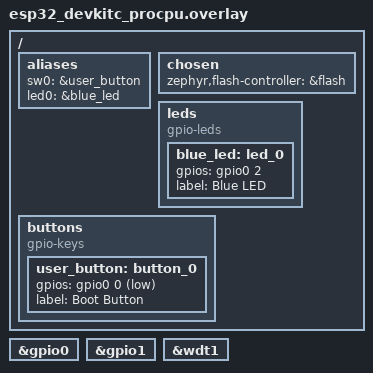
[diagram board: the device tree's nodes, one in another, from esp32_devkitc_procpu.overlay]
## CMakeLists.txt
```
cmake_minimum_required(VERSION 3.20.0)

find_package(Zephyr REQUIRED HINTS $ENV{ZEPHYR_BASE})

project(wol_procpu)

FILE(GLOB app_sources src/*.c)
target_sources(app PRIVATE ${app_sources})

target_include_directories(app PRIVATE
    ${CMAKE_SOURCE_DIR}/inc
    ${CMAKE_SOURCE_DIR}/../shared
)
```

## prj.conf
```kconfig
# --- General ---
CONFIG_EVENTS=y
CONFIG_THREAD_NAME=y
CONFIG_REBOOT=y
CONFIG_WATCHDOG=y

# --- Networking ---
CONFIG_NETWORKING=y
CONFIG_NET_IPV4=y
CONFIG_NET_UDP=y
CONFIG_NET_TCP=y
CONFIG_NET_SOCKETS=y
CONFIG_NET_MAX_CONN=10
CONFIG_NET_MAX_CONTEXTS=10
CONFIG_NET_L2_WIFI_MGMT=y
CONFIG_NET_MGMT=y
CONFIG_NET_MGMT_EVENT=y
CONFIG_NET_IPV4_AUTO=n
CONFIG_NET_DHCPV4=y

# --- Wi-Fi ---
CONFIG_WIFI=y
CONFIG_WIFI_ESP32=y
CONFIG_WIFI_INIT_PRIORITY=60

# --- Storage (NVS Flash) ---
CONFIG_FLASH=y
CONFIG_FLASH_MAP=y
CONFIG_NVS=y
CONFIG_FLASH_PAGE_LAYOUT=y

# --- Hardware ---
CONFIG_GPIO=y

# --- HEAD / STACK ---
CONFIG_LOG_BUFFER_SIZE=1024
CONFIG_LOG_PROCESS_THREAD_STACK_SIZE=1536
CONFIG_NET_MGMT_EVENT_STACK_SIZE=1024
CONFIG_NET_TCP_WORKQ_STACK_SIZE=512
CONFIG_MAIN_STACK_SIZE=4096
CONFIG_SYSTEM_WORKQUEUE_STACK_SIZE=2048
CONFIG_HEAP_MEM_POOL_SIZE=65536
CONFIG_ISR_STACK_SIZE=32768
CONFIG_NET_RX_STACK_SIZE=4096
CONFIG_NET_TX_STACK_SIZE=4096

# --- DEBUG ---
CONFIG_LOG=y
#CONFIG_CONSOLE=n
#CONFIG_UART_CONSOLE=n
CONFIG_THREAD_ANALYZER=y
CONFIG_THREAD_ANALYZER_AUTO=y
CONFIG_THREAD_ANALYZER_AUTO_INTERVAL=30
```

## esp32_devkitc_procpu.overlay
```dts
#include <zephyr/dt-bindings/input/input-event-codes.h>

/ {
	aliases {
		sw0 = &user_button;
		led0 = &blue_led;
	};

	chosen {
		zephyr,flash-controller = &flash;
	};

	leds {
		compatible = "gpio-leds";

		blue_led: led_0 {
			gpios = <&gpio0 2 GPIO_ACTIVE_HIGH>;
			label = "Blue LED";
		};
	};

	buttons {
		compatible = "gpio-keys";

		user_button: button_0 {
			gpios = <&gpio0 0 (GPIO_PULL_UP | GPIO_ACTIVE_LOW)>;
			label = "Boot Button";
		};
	};
};

&gpio0 { status = "okay"; };
&gpio1 { status = "okay"; };
&wdt1  { status = "okay"; };
```

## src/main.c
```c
#include <zephyr/kernel.h>
#include <zephyr/drivers/watchdog.h>
#include <zephyr/sys/reboot.h>
#include <string.h>
#include <stdio.h>

#include "storage.h"
#include "notify.h"
#include "button.h"
#include "wifi.h"
#include "portal.h"
#include "display.h"

#define WDT_TIMEOUT_MS  5000

int main(void) {
    k_msleep(100);

#ifdef CONFIG_SOC_ESP32
    /* Zero shared memory BEFORE appcpu reads it */
    memset((void *)SHARED_STATE(), 0, sizeof(shared_display_state_t));
#endif

    const struct device *wdt_dev = DEVICE_DT_GET(DT_NODELABEL(wdt1));
    int wdt_channel = -1;

    char ssid[32], pass[64], mac[18], pc_ip[INET_ADDRSTRLEN];

    storage_init();
    notify_init();
    button_init();

    if (device_is_ready(wdt_dev)) {
        struct wdt_timeout_cfg wdt_config = {
            .window.max = WDT_TIMEOUT_MS,
            .flags = WDT_FLAG_RESET_SOC
        };
        wdt_channel = wdt_install_timeout(wdt_dev, &wdt_config);
        wdt_setup(wdt_dev, WDT_OPT_PAUSE_HALTED_BY_DBG);
    }

    int rc = storage_read_config(ssid, pass, mac, pc_ip);

    if (rc == 0 && strlen(ssid) > 0 && strlen(mac) == 17) {
        printf("[SYSTEM] Config loaded. Starting Station mode...\n");
        wifi_init_and_connect(ssid, pass, mac, pc_ip);
    } else {
        if (rc == 0) {
            printf("[SYSTEM] Invalid config in Flash. Clearing...\n");
            storage_clear_all();
        }
        printf("[SYSTEM] Starting Portal...\n");
        start_portal();
    }

    printf("\n--- Wake-on-LAN ESP32 DevKitC ---\n");

    while (1) {
#ifdef CONFIG_SOC_ESP32
        bool current_has_ip = SHARED_STATE()->has_ip;
#else
        bool current_has_ip = has_ip;
#endif

        if (!current_has_ip) {
            if (button_is_pressed()) {
                printf("[SYSTEM] FACTORY RESET ACTIVATED!\n");
                storage_clear_all();
                notify_event(NOTIFY_WOL_SENT);
                k_msleep(1000);
                sys_reboot(SYS_REBOOT_COLD);
            }
        }

        if (wdt_channel >= 0) {
            wdt_feed(wdt_dev, wdt_channel);
        }

        k_msleep(500);
    }

    return 0;
}
```

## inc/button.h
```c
#ifndef BUTTON_H
#define BUTTON_H

#include <zephyr/kernel.h>
#include <zephyr/device.h>
#include <zephyr/drivers/gpio.h>
#include <stdio.h>
#include <stdbool.h>

/**
 * @brief Initializes the BOOT button GPIO and its interrupt.
 *        On press: triggers WoL via trigger_wol().
 */
void button_init(void);

/**
 * @brief Checks if the BOOT button is currently pressed.
 *
 * @return true if pressed, false otherwise.
 */
bool button_is_pressed(void);

#endif /* BUTTON_H */
```

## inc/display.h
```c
#ifndef DISPLAY_H
#define DISPLAY_H

#include <zephyr/kernel.h>
#include <zephyr/net/net_ip.h>
#include <stdbool.h>

#ifdef CONFIG_SOC_ESP32

/* On DevKitC (dual-core): display state lives in shared memory.
 * procpu only writes to shared state — no local display variables. */
#include "shared_mem.h"

static inline void display_set_ap_mode(bool v)      { SHARED_STATE()->display_ap_mode    = v; }
static inline void display_set_has_ip(bool v)        { SHARED_STATE()->has_ip              = v; }
static inline void display_notify_start(void)        { SHARED_STATE()->display_start_flag  = 1; }
static inline void display_notify_refresh(void)      { SHARED_STATE()->ui_refresh_flag     = 1; }

/* Compatibility shims so existing call sites in notify.c / wifi.c compile unchanged.
 * sem_ui_refresh and sem_display_start are never used on procpu in dual-core mode —
 * replaced by shared memory flags. Defined as 0 to satisfy the compiler without
 * requiring a real k_sem object. fix #9: removed extern _display_noop_sem. */
#define display_station_ready   (1)
#define sem_ui_refresh          (*((struct k_sem *)NULL))   /* never dereferenced on procpu */
#define sem_display_start       (*((struct k_sem *)NULL))

#else

/* On ESP32-C3 (single-core): original semaphore-based interface */
extern struct k_sem sem_display_start;
extern struct k_sem sem_ui_refresh;

extern bool display_ap_mode;
extern bool display_wifi_ready;
extern bool display_station_ready;
extern bool has_ip;

#endif /* CONFIG_SOC_ESP32 */

void display_task_entry(void *p1, void *p2, void *p3);

#endif /* DISPLAY_H */
```

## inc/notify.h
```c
#ifndef NOTIFY_H
#define NOTIFY_H

#include <zephyr/kernel.h>
#include <zephyr/drivers/gpio.h>

/* Notification types */
typedef enum {
    NOTIFY_WOL_SENT,    /* 2 Blinks (500ms ON, 200ms OFF) */
    NOTIFY_PING_UPDATE  /* 1 Blink  (500ms ON) */
} notify_type_t;

/**
 * @brief Initialize GPIO for the Blue LED.
 */
void notify_init(void);

/**
 * @brief Notify the user of an event by blinking the blue LED.
 *        Also signals the display to refresh (shared memory on DevKitC,
 *        semaphore on ESP32-C3).
 *
 *        - NOTIFY_WOL_SENT:   2 blinks (500ms ON, 200ms OFF)
 *        - NOTIFY_PING_UPDATE: 1 blink  (500ms ON)
 */
void notify_event(notify_type_t type);

#endif /* NOTIFY_H */
```

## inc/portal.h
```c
#ifndef PORTAL_H
#define PORTAL_H

#include <zephyr/kernel.h>
#include <zephyr/net/socket.h>
#include <zephyr/net/wifi_mgmt.h>
#include <zephyr/net/net_if.h>
#include <zephyr/net/net_mgmt.h>
#include <zephyr/net/net_ip.h>
#include <zephyr/sys/reboot.h>
#include <stdlib.h>
#include <string.h>
#include <ctype.h>

/**
 * @brief Starts the Captive Portal.
 *
 * 1. Enables Wi-Fi Access Point mode (SSID: WOL_ESP).
 * 2. Sets a static IP (192.168.4.1).
 * 3. Starts the DNS redirector task (intercepts all DNS queries).
 * 4. Starts the HTTP server (serves the configuration form).
 *
 * On ESP32 DevKitC (dual-core): also signals the appcpu display
 * thread via shared memory before starting the AP.
 */
void start_portal(void);

/**
 * @brief Stops the Captive Portal and disables AP mode.
 */
void stop_portal(void);

#endif /* PORTAL_H */
```

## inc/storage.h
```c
#ifndef STORAGE_H
#define STORAGE_H

#include <zephyr/kernel.h>
#include <zephyr/device.h>
#include <zephyr/drivers/flash.h>
#include <zephyr/fs/nvs.h>
#include <zephyr/net/net_ip.h>
#include <string.h>
#include <zephyr/types.h>

/* Unique IDs for each NVS entry */
#define STORAGE_ID_SSID     1
#define STORAGE_ID_PASS     2
#define STORAGE_ID_MAC      3
#define STORAGE_ID_IP       4

/**
 * @brief Initializes the NVS storage subsystem.
 */
void storage_init(void);

/**
 * @brief Saves Wi-Fi settings and target PC MAC/IP to Flash.
 *
 * @param s  Wi-Fi SSID.
 * @param p  Wi-Fi password.
 * @param m  Target MAC address ("AA:BB:CC:DD:EE:FF").
 * @param ip Target PC IP address ("192.168.1.100").
 * @return 0 on success.
 */
int storage_write_config(const char *s, const char *p,
                         const char *m, const char *ip);

/**
 * @brief Reads saved settings from Flash.
 *
 * @param s  Buffer for SSID  (min 32 bytes).
 * @param p  Buffer for password (min 64 bytes).
 * @param m  Buffer for MAC   (min 18 bytes).
 * @param ip Buffer for IP    (min INET_ADDRSTRLEN bytes).
 * @return 0 on success, -1 if Flash is empty.
 */
int storage_read_config(char *s, char *p, char *m, char *ip);

/**
 * @brief Erases all settings from Flash (Factory Reset).
 */
void storage_clear_all(void);

#endif /* STORAGE_H */
```

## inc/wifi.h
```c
#ifndef WIFI_H
#define WIFI_H

#include <zephyr/kernel.h>
#include <zephyr/net/net_if.h>
#include <zephyr/net/net_mgmt.h>
#include <zephyr/net/wifi_mgmt.h>
#include <zephyr/net/net_event.h>
#include <zephyr/net/socket.h>
#include <zephyr/net/icmp.h>
#include <zephyr/net/net_ip.h>
#include <zephyr/net/dhcpv4.h>
#include <stdio.h>
#include <string.h>
#include <errno.h>
#include <stdbool.h>

/**
 * Global variables — defined in wifi.c.
 *
 * On ESP32-C3 (single-core): accessed directly by display.c.
 * On ESP32 DevKitC (dual-core): procpu-local only; display reads
 * from shared memory via shared_mem.h instead.
 */
extern char global_ip_str[INET_ADDRSTRLEN];
extern bool last_known_state;
extern char target_pc_ip[INET_ADDRSTRLEN];

/**
 * @brief Initializes the Wi-Fi stack and attempts to connect.
 *
 * @param ssid  The Wi-Fi network name from Flash.
 * @param pass  The Wi-Fi password from Flash.
 * @param mac   The target PC MAC address (string "AA:BB:CC:DD:EE:FF").
 * @param pc_ip The target PC IP address (string "192.168.1.100").
 */
void wifi_init_and_connect(const char *ssid, const char *pass,
                           const char *mac,  const char *pc_ip);

/**
 * @brief Submits a Wake-on-LAN Magic Packet task to the system workqueue.
 *        Called by the button interrupt handler in button.c.
 */
void trigger_wol(void);

#endif /* WIFI_H */
```

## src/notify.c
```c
#include "notify.h"
#include "display.h"

static const struct gpio_dt_spec blue_led = GPIO_DT_SPEC_GET(DT_NODELABEL(blue_led), gpios);

static K_SEM_DEFINE(sem_blink, 0, 1);
static int blink_count;

static void blink_thread(void *p1, void *p2, void *p3) {
    while (1) {
        k_sem_take(&sem_blink, K_FOREVER);

        for (int i = 0; i < blink_count; i++) {
            gpio_pin_set_dt(&blue_led, 1);
            k_msleep(500);
            gpio_pin_set_dt(&blue_led, 0);
            if (i < blink_count - 1) {
                k_msleep(200);
            }
        }
    }
}
K_THREAD_DEFINE(blink_tid, 512, blink_thread, NULL, NULL, NULL, 10, 0, 0);

void notify_init(void) {
    if (!device_is_ready(blue_led.port)) {
        return;
    }
    gpio_pin_configure_dt(&blue_led, GPIO_OUTPUT_INACTIVE);
}

void notify_event(notify_type_t type) {
#ifdef CONFIG_SOC_ESP32
    /* Dual-core: signal appcpu via shared memory flag */
    display_notify_refresh();
#else
    /* Single-core: original semaphore */
    if (display_station_ready) {
        k_sem_give(&sem_ui_refresh);
    }
#endif

    blink_count = (type == NOTIFY_WOL_SENT) ? 2 : 1;
    k_sem_give(&sem_blink);
}
```

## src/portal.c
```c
#include "portal.h"
#include "portal_html.h"
#include "storage.h"
#include "notify.h"
#include "display.h"

static bool portal_active = false;

static void send_all(int sock, const char *data, int len) {
    while (len > 0) {
        int sent = zsock_send(sock, data, len, 0);
        if (sent <= 0) break;
        data += sent;
        len  -= sent;
    }
}

static void send_form(int client, bool with_err) {
    const char *hdr =
        "HTTP/1.1 200 OK\r\nContent-Type: text/html\r\n"
        "Connection: close\r\n\r\n";
    send_all(client, hdr,     strlen(hdr));
    send_all(client, html_p1, strlen(html_p1));
    send_all(client, html_p2, strlen(html_p2));
    send_all(client, html_p3, strlen(html_p3));
    send_all(client, html_p4, strlen(html_p4));
    if (with_err) {
        send_all(client, html_err, strlen(html_err));
    }
    send_all(client, html_tail, strlen(html_tail));
}

static void extract_field(const char *body, const char *key, char *out, size_t out_len) {
    const char *p = strstr(body, key);
    if (!p) { out[0] = '\0'; return; }
    p += strlen(key) + 1;
    size_t i = 0;
    while (*p && *p != '&' && i < out_len - 1) {
        out[i++] = *p++;
    }
    out[i] = '\0';
}

static void url_decode(char *dst, const char *src, size_t dst_len) {
    size_t i = 0;
    while (*src && i < dst_len - 1) {
        if (*src == '%' && src[1] && src[2]) {
            char hex[3] = { src[1], src[2], '\0' };
            dst[i++] = (char)strtol(hex, NULL, 16);
            src += 3;
        } else if (*src == '+') {
            dst[i++] = ' ';
            src++;
        } else {
            dst[i++] = *src++;
        }
    }
    dst[i] = '\0';
}

static bool is_valid_mac(const char *mac) {
    if (strlen(mac) != 17) return false;
    for (int i = 0; i < 17; i++) {
        if (i % 3 == 2) {
            if (mac[i] != ':') return false;
        } else {
            if (!isxdigit((unsigned char)mac[i])) return false;
        }
    }
    return true;
}

static void http_server_task(void *p1, void *p2, void *p3) {
    while (!portal_active) { k_msleep(100); }

    int server = zsock_socket(AF_INET, SOCK_STREAM, IPPROTO_TCP);
    if (server < 0) { return; }

    int opt = 1;
    zsock_setsockopt(server, SOL_SOCKET, SO_REUSEADDR, &opt, sizeof(opt));

    struct sockaddr_in addr = {
        .sin_family      = AF_INET,
        .sin_port        = htons(80),
        .sin_addr.s_addr = INADDR_ANY,
    };
    zsock_bind(server, (struct sockaddr *)&addr, sizeof(addr));
    zsock_listen(server, 2);

    static char buf[1024];

    while (1) {
        int client = zsock_accept(server, NULL, NULL);
        if (client < 0) continue;

        int total = 0, content_length = 0;
        bool headers_done = false;
        char *body_start = NULL;
        memset(buf, 0, sizeof(buf));

        while (total < (int)sizeof(buf) - 1) {
            int n = zsock_recv(client, buf + total, sizeof(buf) - 1 - total, 0);
            if (n <= 0) break;
            total += n;
            buf[total] = '\0';

            if (!headers_done) {
                body_start = strstr(buf, "\r\n\r\n");
                if (body_start) {
                    headers_done = true;
                    body_start += 4;
                    char *cl = strstr(buf, "Content-Length:");
                    if (!cl) cl = strstr(buf, "content-length:");
                    if (cl) content_length = atoi(cl + 15);
                }
            }
            if (headers_done && content_length > 0) {
                if ((total - (int)(body_start - buf)) >= content_length) break;
            } else if (headers_done) {
                break;
            }
        }

        if (!headers_done || !body_start) { zsock_close(client); continue; }

        if (strncmp(buf, "POST /save", 10) == 0) {
            char raw_ssid[32]={0}, raw_pass[64]={0}, raw_mac[64]={0}, raw_ip[32]={0};
            extract_field(body_start, "s", raw_ssid, sizeof(raw_ssid));
            extract_field(body_start, "p", raw_pass, sizeof(raw_pass));
            extract_field(body_start, "i", raw_ip,   sizeof(raw_ip));
            extract_field(body_start, "m", raw_mac,  sizeof(raw_mac));

            char ssid[32]={0}, pass[64]={0}, mac[18]={0}, pc_ip[INET_ADDRSTRLEN]={0};
            url_decode(ssid,  raw_ssid, sizeof(ssid));
            url_decode(pass,  raw_pass, sizeof(pass));
            url_decode(pc_ip, raw_ip,   sizeof(pc_ip));
            url_decode(mac,   raw_mac,  sizeof(mac));

            struct in_addr tmp;
            bool ip_ok = (strlen(pc_ip) > 0 && zsock_inet_pton(AF_INET, pc_ip, &tmp) == 1);

            if (strlen(ssid) == 0 || !is_valid_mac(mac) || !ip_ok) {
                send_form(client, true);
                zsock_close(client);
                continue;
            }

            storage_write_config(ssid, pass, mac, pc_ip);
            send_all(client, html_ok, strlen(html_ok));
            k_msleep(200);
            zsock_close(client);
            notify_event(NOTIFY_WOL_SENT);
            k_msleep(1000);
            sys_reboot(SYS_REBOOT_COLD);
        } else {
            send_form(client, false);
        }
        zsock_close(client);
    }
}
K_THREAD_DEFINE(http_tid, 4096, http_server_task, NULL, NULL, NULL, 7, 0, 0);

static void dhcp_server_task(void *p1, void *p2, void *p3) {
    while (!portal_active) { k_msleep(100); }

    int sock = zsock_socket(AF_INET, SOCK_DGRAM, IPPROTO_UDP);
    if (sock < 0) { return; }

    int opt = 1;
    zsock_setsockopt(sock, SOL_SOCKET, SO_REUSEADDR, &opt, sizeof(opt));

    struct sockaddr_in addr = {
        .sin_family      = AF_INET,
        .sin_port        = htons(67),
        .sin_addr.s_addr = INADDR_ANY,
    };
    zsock_bind(sock, (struct sockaddr *)&addr, sizeof(addr));

    uint8_t buf[300];
    while (1) {
        struct sockaddr_in client_addr;
        socklen_t addr_len = sizeof(client_addr);
        int len = zsock_recvfrom(sock, buf, sizeof(buf), 0,
                                 (struct sockaddr *)&client_addr, &addr_len);
        if (len < 240 || buf[0] != 1) continue;

        uint8_t reply[300];
        memset(reply, 0, sizeof(reply));
        reply[0] = 2; reply[1] = buf[1]; reply[2] = buf[2]; reply[3] = buf[3];
        memcpy(&reply[4], &buf[4], 4);
        reply[10] = buf[10]; reply[11] = buf[11];
        reply[16] = 192; reply[17] = 168; reply[18] = 4; reply[19] = 2;
        reply[20] = 192; reply[21] = 168; reply[22] = 4; reply[23] = 1;
        memcpy(&reply[28], &buf[28], 6);
        reply[236] = 99; reply[237] = 130; reply[238] = 83; reply[239] = 99;

        int i = 240;
        uint8_t msg_type = (buf[242] == 1) ? 2 : 5;
        reply[i++] = 53; reply[i++] = 1; reply[i++] = msg_type;
        reply[i++] = 54; reply[i++] = 4;
        reply[i++] = 192; reply[i++] = 168; reply[i++] = 4; reply[i++] = 1;
        reply[i++] = 51; reply[i++] = 4;
        reply[i++] = 0; reply[i++] = 0; reply[i++] = 0x0e; reply[i++] = 0x10;
        reply[i++] = 1; reply[i++] = 4;
        reply[i++] = 255; reply[i++] = 255; reply[i++] = 255; reply[i++] = 0;
        reply[i++] = 3; reply[i++] = 4;
        reply[i++] = 192; reply[i++] = 168; reply[i++] = 4; reply[i++] = 1;
        reply[i++] = 6; reply[i++] = 4;
        reply[i++] = 192; reply[i++] = 168; reply[i++] = 4; reply[i++] = 1;
        reply[i++] = 255;

        struct sockaddr_in dst = {
            .sin_family      = AF_INET,
            .sin_port        = htons(68),
            .sin_addr.s_addr = INADDR_BROADCAST,
        };
        zsock_sendto(sock, reply, i, 0, (struct sockaddr *)&dst, sizeof(dst));
    }
}
K_THREAD_DEFINE(dhcp_tid, 2048, dhcp_server_task, NULL, NULL, NULL, 7, 0, 0);

static void dns_server_task(void *p1, void *p2, void *p3) {
    while (!portal_active) { k_msleep(100); }

    int sock = zsock_socket(AF_INET, SOCK_DGRAM, IPPROTO_UDP);
    if (sock < 0) { return; }

    struct sockaddr_in addr = {
        .sin_family      = AF_INET,
        .sin_port        = htons(53),
        .sin_addr.s_addr = INADDR_ANY,
    };
    zsock_bind(sock, (struct sockaddr *)&addr, sizeof(addr));

    uint8_t buffer[512];
    while (1) {
        struct sockaddr client_addr;
        socklen_t addr_len = sizeof(client_addr);
        int len = zsock_recvfrom(sock, buffer, sizeof(buffer), 0,
                                 &client_addr, &addr_len);
        if (len > 0) {
            buffer[2] |= 0x80;
            zsock_sendto(sock, buffer, len, 0, &client_addr, addr_len);
        }
    }
}
K_THREAD_DEFINE(dns_tid, 2048, dns_server_task, NULL, NULL, NULL, 8, 0, 0);

void start_portal(void) {
#ifdef CONFIG_SOC_ESP32
    SHARED_STATE()->display_ap_mode = true;
    display_notify_start();
#else
    display_ap_mode = true;
#endif

    struct net_if *iface = net_if_get_default();
    struct in_addr gw, mask, my_addr;
    zsock_inet_pton(AF_INET, "192.168.4.1", &my_addr);
    zsock_inet_pton(AF_INET, "192.168.4.1", &gw);
    zsock_inet_pton(AF_INET, "255.255.255.0", &mask);
    net_if_ipv4_set_gw(iface, &gw);
    net_if_ipv4_addr_add(iface, &my_addr, NET_ADDR_MANUAL, 0);
    net_if_ipv4_set_netmask_by_addr(iface, &my_addr, &mask);

    struct wifi_connect_req_params params = {
        .ssid        = "WOL_ESP",
        .ssid_length = 7,
        .security    = WIFI_SECURITY_TYPE_NONE,
        .channel     = 1,
        .band        = WIFI_FREQ_BAND_2_4_GHZ,
        .mfp         = WIFI_MFP_DISABLE,
    };

    printk("[PORTAL] AP Mode Starting...\n");
    int ret = net_mgmt(NET_REQUEST_WIFI_AP_ENABLE, iface, &params, sizeof(params));
    if (ret) {
        printk("[PORTAL] AP enable failed: %d\n", ret);
        return;
    }
    printk("[PORTAL] AP up: 192.168.4.1\n");
    portal_active = true;
}
```

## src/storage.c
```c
#include "storage.h"

#define STORAGE_NODE DT_NODE_BY_FIXED_PARTITION_LABEL(storage)
#define FLASH_NODE DT_MTD_FROM_FIXED_PARTITION(STORAGE_NODE)

static struct nvs_fs fs;

void storage_init(void) {
    int rc;
    struct flash_pages_info info;
    const struct device *flash_dev = DEVICE_DT_GET(FLASH_NODE);

    if (!device_is_ready(flash_dev)) {
        printk("Error: Flash device not ready\n");
        return;
    }

    fs.flash_device = flash_dev;
    fs.offset = DT_REG_ADDR(STORAGE_NODE);
    
    rc = flash_get_page_info_by_offs(flash_dev, fs.offset, &info);
    if (rc) {
        printk("Error getting page info (%d)\n", rc);
        return;
    }

    fs.sector_size = info.size;
    fs.sector_count = 3;                                                /* Reserve 3 sectors for NVS */

    rc = nvs_mount(&fs);
    if (rc) {
        printk("Error mounting NVS (%d)\n", rc);
    }
}

int storage_write_config(const char *s, const char *p, const char *m, const char *ip) {
    nvs_write(&fs, STORAGE_ID_SSID, s,  strlen(s)  + 1);
    nvs_write(&fs, STORAGE_ID_PASS, p,  strlen(p)  + 1);
    nvs_write(&fs, STORAGE_ID_MAC,  m,  strlen(m)  + 1);
    nvs_write(&fs, STORAGE_ID_IP,   ip, strlen(ip) + 1);
    return 0;
}

int storage_read_config(char *s, char *p, char *m, char *ip) {
    if (nvs_read(&fs, STORAGE_ID_SSID, s, 32) <= 0) return -1;
    nvs_read(&fs, STORAGE_ID_PASS, p,  64);
    nvs_read(&fs, STORAGE_ID_MAC,  m,  18);
    nvs_read(&fs, STORAGE_ID_IP,   ip, INET_ADDRSTRLEN);
    return 0;
}

void storage_clear_all(void) {
    nvs_delete(&fs, STORAGE_ID_SSID);
    nvs_delete(&fs, STORAGE_ID_PASS);
    nvs_delete(&fs, STORAGE_ID_MAC);
    nvs_delete(&fs, STORAGE_ID_IP);
}
```

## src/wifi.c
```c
#include "wifi.h"
#include "notify.h"
#include "storage.h"
#include "display.h"

#define WOL_PORT    9

static struct net_icmp_ctx ping_ctx;
static struct k_work_delayable ping_work;
static volatile bool target_is_online   = false;
bool last_known_state                   = false;
static bool first_ping_done             = false;
static uint16_t ping_seq                = 0;
static uint8_t ping_attempts            = 0;

static bool wifi_connected              = false;

static char saved_ssid[32];
static char saved_pass[64];
static char saved_mac_str[18];
static uint8_t target_mac_bin[6];
char target_pc_ip[INET_ADDRSTRLEN]      = "255.255.255.255";
char global_ip_str[INET_ADDRSTRLEN]     = "";

static struct net_mgmt_event_callback wifi_cb;
static struct net_mgmt_event_callback ipv4_cb;
static struct k_work wol_work;
static struct k_work_delayable reconnect_work;

/* --- Shared memory sync helper --- */
static inline void sync_to_shared(void) {
#ifdef CONFIG_SOC_ESP32
    volatile shared_display_state_t *s = SHARED_STATE();
    strncpy((char *)s->global_ip_str, global_ip_str, sizeof(s->global_ip_str) - 1);
    strncpy((char *)s->target_pc_ip,  target_pc_ip,  sizeof(s->target_pc_ip)  - 1);
    s->last_known_state = last_known_state;
    s->has_ip = (strlen(global_ip_str) > 0 && strcmp(global_ip_str, "0.0.0.0") != 0);
#endif
}

static void parse_mac_address(const char *mac_str, uint8_t *mac_bin) {
    for (int i = 0; i < 6; i++) {
        char byte_str[3] = { mac_str[i * 3], mac_str[i * 3 + 1], '\0' };
        mac_bin[i] = (uint8_t)strtol(byte_str, NULL, 16);
    }
}

static void reconnect_worker(struct k_work *work) {
    struct net_if *iface = net_if_get_default();
    struct wifi_connect_req_params params = {
        .ssid        = (uint8_t *)saved_ssid,
        .ssid_length = strlen(saved_ssid),
        .psk         = (uint8_t *)saved_pass,
        .psk_length  = strlen(saved_pass),
        .channel     = WIFI_CHANNEL_ANY,
        .security    = WIFI_SECURITY_TYPE_PSK,
        .band        = WIFI_FREQ_BAND_2_4_GHZ,
    };
    printk("[WIFI] Reconnecting to %s...\n", saved_ssid);
    net_mgmt(NET_REQUEST_WIFI_CONNECT, iface, &params, sizeof(params));
}

static void send_wol_worker(struct k_work *work) {
    if (strlen(global_ip_str) == 0 || strcmp(global_ip_str, "0.0.0.0") == 0) {
        printk("[WOL] No IP — WoL cancelled\n");
        return;
    }

    uint8_t pkt[102];
    struct sockaddr_in dest;

    memset(pkt, 0xFF, 6);
    for (int i = 1; i <= 16; i++) {
        memcpy(&pkt[i * 6], target_mac_bin, 6);
    }

    int sock = zsock_socket(AF_INET, SOCK_DGRAM, IPPROTO_UDP);
    if (sock < 0) { return; }

    int opt = 1;
    zsock_setsockopt(sock, SOL_SOCKET, SO_BROADCAST, &opt, sizeof(opt));

    dest.sin_family      = AF_INET;
    dest.sin_port        = htons(WOL_PORT);
    dest.sin_addr.s_addr = INADDR_BROADCAST;

    if (zsock_sendto(sock, pkt, sizeof(pkt), 0,
                     (struct sockaddr *)&dest, sizeof(dest)) > 0) {
        printk("[WIFI] WoL Magic Packet Sent to %s\n", saved_mac_str);
        notify_event(NOTIFY_WOL_SENT);
    }
    zsock_close(sock);
}

void trigger_wol(void) {
    k_work_submit(&wol_work);
}

static int ping_handler(struct net_icmp_ctx *ctx, struct net_pkt *pkt,
                        struct net_icmp_ip_hdr *ip_hdr, struct net_icmp_hdr *icmp_hdr,
                        void *user_data) {
    target_is_online = true;
    return 0;
}

static void ping_worker_handler(struct k_work *work) {
    if (ping_attempts > 0) {
        if (target_is_online) {
            if (!first_ping_done || !last_known_state) {
                last_known_state = true;
                first_ping_done  = true;
                sync_to_shared();
                notify_event(NOTIFY_PING_UPDATE);
            }
            ping_attempts = 0;
            k_work_reschedule(&ping_work, K_MINUTES(1));
            return;
        } else if (ping_attempts >= 3) {
            if (!first_ping_done || last_known_state) {
                last_known_state = false;
                first_ping_done  = true;
                sync_to_shared();
                notify_event(NOTIFY_PING_UPDATE);
            }
            ping_attempts = 0;
            k_work_reschedule(&ping_work, K_MINUTES(1));
            return;
        }
    }

    target_is_online = false;
    ping_attempts++;

    struct sockaddr_in dest;
    dest.sin_family = AF_INET;
    zsock_inet_pton(AF_INET, target_pc_ip, &dest.sin_addr);

    struct net_icmp_ping_params params = {
        .identifier = 0x1234,
        .sequence   = ping_seq++,
    };

    net_icmp_send_echo_request(&ping_ctx, net_if_get_default(),
                               (struct sockaddr *)&dest, &params, NULL);
    k_work_reschedule(&ping_work, K_SECONDS(1));
}

static void handle_wifi_events(struct net_mgmt_event_callback *cb,
                                uint64_t mgmt_event, struct net_if *iface) {
    if (mgmt_event == NET_EVENT_WIFI_CONNECT_RESULT) {
        wifi_connected = true;
        printk("[WIFI] Connected!\n");
        net_dhcpv4_start(iface);
    }

    if (mgmt_event == NET_EVENT_WIFI_DISCONNECT_RESULT) {
        if (!wifi_connected) return;
        wifi_connected = false;
        printk("[WIFI] Disconnected — reconnecting in 3s...\n");
        net_dhcpv4_stop(iface);
        last_known_state = false;
        global_ip_str[0] = '\0';
        sync_to_shared();
#ifdef CONFIG_SOC_ESP32
        display_notify_refresh();
#else
        k_sem_give(&sem_ui_refresh);
#endif
        k_work_reschedule(&reconnect_work, K_SECONDS(3));
    }
}

static void handle_ipv4_events(struct net_mgmt_event_callback *cb,
                                uint64_t mgmt_event, struct net_if *iface) {
    if (mgmt_event == NET_EVENT_IPV4_ADDR_ADD) {
        struct net_if_ipv4 *ipv4 = iface->config.ip.ipv4;
        if (!ipv4) return;

        for (int i = 0; i < NET_IF_MAX_IPV4_ADDR; i++) {
            struct net_if_addr *addr = &ipv4->unicast[i].ipv4;
            if (addr->is_used && addr->addr_state == NET_ADDR_PREFERRED) {
                zsock_inet_ntop(AF_INET,
                    &ipv4->unicast[i].ipv4.address.in_addr,
                    global_ip_str, sizeof(global_ip_str));
                sync_to_shared();
#ifdef CONFIG_SOC_ESP32
                display_notify_refresh();
#else
                k_sem_give(&sem_ui_refresh);
#endif
                k_work_reschedule(&ping_work, K_NO_WAIT);
                break;
            }
        }
    }
}

void wifi_init_and_connect(const char *ssid, const char *pass, const char *mac, const char *pc_ip) {
    strncpy(saved_ssid,    ssid, sizeof(saved_ssid) - 1);
    strncpy(saved_pass,    pass, sizeof(saved_pass) - 1);
    strncpy(saved_mac_str, mac,  sizeof(saved_mac_str) - 1);
    strncpy(target_pc_ip,  pc_ip, sizeof(target_pc_ip) - 1);

    parse_mac_address(saved_mac_str, target_mac_bin);

    /* Initialise shared memory region */
    sync_to_shared();
#ifdef CONFIG_SOC_ESP32
    strncpy((char *)SHARED_STATE()->target_pc_ip, target_pc_ip, INET_ADDRSTRLEN - 1);
#endif

    k_work_init(&wol_work, send_wol_worker);
    k_work_init_delayable(&ping_work, ping_worker_handler);
    k_work_init_delayable(&reconnect_work, reconnect_worker);
    net_icmp_init_ctx(&ping_ctx, AF_INET, NET_ICMPV4_ECHO_REPLY, 0, ping_handler);

    net_mgmt_init_event_callback(&wifi_cb, handle_wifi_events,
                              NET_EVENT_WIFI_CONNECT_RESULT |
                              NET_EVENT_WIFI_DISCONNECT_RESULT);
    net_mgmt_add_event_callback(&wifi_cb);

    net_mgmt_init_event_callback(&ipv4_cb, handle_ipv4_events,
                                  NET_EVENT_IPV4_ADDR_ADD);
    net_mgmt_add_event_callback(&ipv4_cb);

    struct net_if *iface = net_if_get_default();
    struct wifi_connect_req_params params = {
        .ssid        = (uint8_t *)saved_ssid,
        .ssid_length = strlen(saved_ssid),
        .psk         = (uint8_t *)saved_pass,
        .psk_length  = strlen(saved_pass),
        .channel     = WIFI_CHANNEL_ANY,
        .security    = WIFI_SECURITY_TYPE_PSK,
        .band        = WIFI_FREQ_BAND_2_4_GHZ,
    };

#ifdef CONFIG_SOC_ESP32
    display_notify_start();   /* signal appcpu to start display thread */
#else
    k_sem_give(&sem_display_start);
#endif

    printf("[WIFI] Connecting to %s...\n", saved_ssid);
    net_mgmt(NET_REQUEST_WIFI_CONNECT, iface, &params, sizeof(params));
}
```
